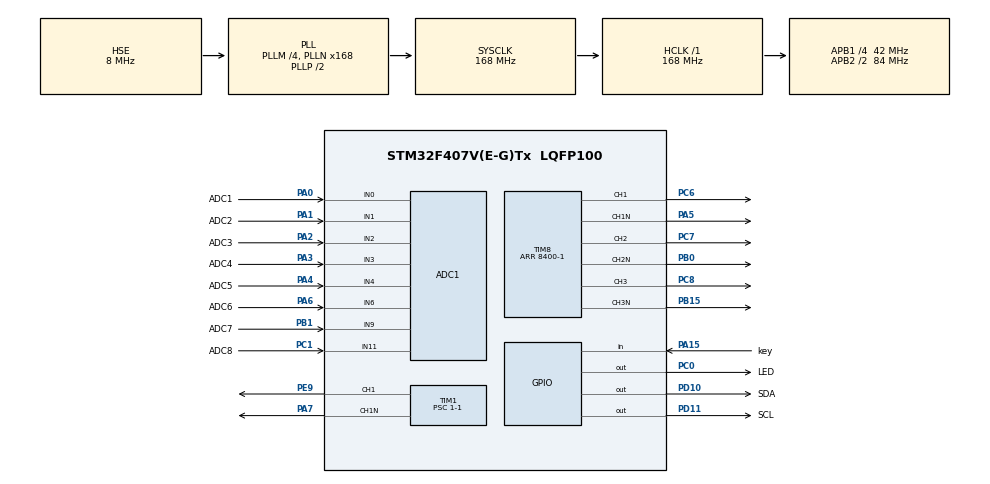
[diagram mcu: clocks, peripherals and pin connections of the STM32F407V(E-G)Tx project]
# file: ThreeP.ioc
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ADC1.Channel-14\#ChannelRegularConversion=ADC_CHANNEL_4
ADC1.Channel-15\#ChannelRegularConversion=ADC_CHANNEL_6
ADC1.Channel-16\#ChannelRegularConversion=ADC_CHANNEL_9
ADC1.Channel-17\#ChannelRegularConversion=ADC_CHANNEL_11
ADC1.Channel-5\#ChannelRegularConversion=ADC_CHANNEL_0
ADC1.Channel-6\#ChannelRegularConversion=ADC_CHANNEL_1
ADC1.Channel-7\#ChannelRegularConversion=ADC_CHANNEL_2
ADC1.Channel-9\#ChannelRegularConversion=ADC_CHANNEL_3
ADC1.ContinuousConvMode=ENABLE
ADC1.DMAContinuousRequests=ENABLE
ADC1.InjNumberOfConversion=0
ADC1.NbrOfConversion=8
ADC1.NbrOfConversionFlag=1
ADC1.Rank-14\#ChannelRegularConversion=5
ADC1.Rank-15\#ChannelRegularConversion=6
ADC1.Rank-16\#ChannelRegularConversion=7
ADC1.Rank-17\#ChannelRegularConversion=8
ADC1.Rank-5\#ChannelRegularConversion=1
ADC1.Rank-6\#ChannelRegularConversion=2
ADC1.Rank-7\#ChannelRegularConversion=3
ADC1.Rank-9\#ChannelRegularConversion=4
ADC1.SamplingTime-14\#ChannelRegularConversion=ADC_SAMPLETIME_15CYCLES
ADC1.SamplingTime-15\#ChannelRegularConversion=ADC_SAMPLETIME_15CYCLES
ADC1.SamplingTime-16\#ChannelRegularConversion=ADC_SAMPLETIME_15CYCLES
ADC1.SamplingTime-17\#ChannelRegularConversion=ADC_SAMPLETIME_15CYCLES
ADC1.SamplingTime-5\#ChannelRegularConversion=ADC_SAMPLETIME_15CYCLES
ADC1.SamplingTime-6\#ChannelRegularConversion=ADC_SAMPLETIME_15CYCLES
ADC1.SamplingTime-7\#ChannelRegularConversion=ADC_SAMPLETIME_15CYCLES
ADC1.SamplingTime-9\#ChannelRegularConversion=ADC_SAMPLETIME_15CYCLES
ADC1.ScanConvMode=ENABLE
ADC1.master=1
Dma.ADC1.0.Direction=DMA_PERIPH_TO_MEMORY
Dma.ADC1.0.FIFOMode=DMA_FIFOMODE_DISABLE
Dma.ADC1.0.Instance=DMA2_Stream0
Dma.ADC1.0.MemDataAlignment=DMA_MDATAALIGN_HALFWORD
Dma.ADC1.0.MemInc=DMA_MINC_ENABLE
Dma.ADC1.0.Mode=DMA_CIRCULAR
Dma.ADC1.0.PeriphDataAlignment=DMA_PDATAALIGN_HALFWORD
Dma.ADC1.0.PeriphInc=DMA_PINC_DISABLE
Dma.ADC1.0.Priority=DMA_PRIORITY_VERY_HIGH
Dma.Request0=ADC1
Mcu.Family=STM32F4
Mcu.Name=STM32F407V(E-G)Tx
Mcu.Package=LQFP100
NVIC.ADC_IRQn=true\:0\:0\:false\:false\:true\:true\:true
NVIC.DMA2_Stream0_IRQn=true\:0\:0\:false\:false\:true\:false\:true
NVIC.PriorityGroup=NVIC_PRIORITYGROUP_4
NVIC.TIM1_UP_TIM10_IRQn=true\:1\:0\:true\:false\:true\:true\:true
NVIC.TIM8_UP_TIM13_IRQn=true\:1\:0\:true\:false\:true\:true\:true
PA0-WKUP.GPIO_Label=ADC1
PA0-WKUP.Signal=ADCx_IN0
PA1.GPIO_Label=ADC2
PA1.Signal=ADCx_IN1
PA13.Mode=Serial_Wire
PA13.Signal=SYS_JTMS-SWDIO
PA14.Mode=Serial_Wire
PA14.Signal=SYS_JTCK-SWCLK
PA15.GPIO_Label=key
PA15.GPIO_PuPd=GPIO_PULLUP
PA15.Signal=GPIO_Input
PA2.GPIO_Label=ADC3
PA2.Signal=ADCx_IN2
PA3.GPIO_Label=ADC4
PA3.Signal=ADCx_IN3
PA4.GPIO_Label=ADC5
PA4.Signal=ADCx_IN4
PA5.Mode=PWM Generation1 CH1 CH1N
PA5.Signal=TIM8_CH1N
PA6.GPIO_Label=ADC6
PA6.Signal=ADCx_IN6
PA7.GPIO_PuPd=GPIO_NOPULL
PA7.GPIO_Speed=GPIO_SPEED_FREQ_HIGH
PA7.Mode=PWM Generation1 CH1 CH1N
PA7.Signal=TIM1_CH1N
PB0.Mode=PWM Generation2 CH2 CH2N
PB0.Signal=TIM8_CH2N
PB1.GPIO_Label=ADC7
PB1.Signal=ADCx_IN9
PB15.Mode=PWM Generation3 CH3 CH3N
PB15.Signal=TIM8_CH3N
PC0.GPIO_Label=LED
PC0.Signal=GPIO_Output
PC1.GPIO_Label=ADC8
PC1.Signal=ADCx_IN11
PC6.Signal=S_TIM8_CH1
PC7.Signal=S_TIM8_CH2
PC8.Signal=S_TIM8_CH3
PD10.GPIO_Label=SDA
PD10.Signal=GPIO_Output
PD11.GPIO_Label=SCL
PD11.Signal=GPIO_Output
PE9.GPIO_Speed=GPIO_SPEED_FREQ_HIGH
PE9.Signal=S_TIM1_CH1
PH0-OSC_IN.Mode=HSE-External-Oscillator
PH0-OSC_IN.Signal=RCC_OSC_IN
PH1-OSC_OUT.Mode=HSE-External-Oscillator
PH1-OSC_OUT.Signal=RCC_OSC_OUT
ProjectManager.HeapSize=0x2000
ProjectManager.StackSize=0x2000
ProjectManager.TargetToolchain=MDK-ARM V5.27
RCC.48MHZClocksFreq_Value=84000000
RCC.AHBFreq_Value=168000000
RCC.APB1CLKDivider=RCC_HCLK_DIV4
RCC.APB1Freq_Value=42000000
RCC.APB1TimFreq_Value=84000000
RCC.APB2CLKDivider=RCC_HCLK_DIV2
RCC.APB2Freq_Value=84000000
RCC.APB2TimFreq_Value=168000000
RCC.CortexFreq_Value=168000000
RCC.HCLKFreq_Value=168000000
RCC.HSE_VALUE=8000000
RCC.HSI_VALUE=16000000
RCC.LSE_VALUE=32768
RCC.PLLM=4
RCC.PLLN=168
RCC.PLLSourceVirtual=RCC_PLLSOURCE_HSE
RCC.SYSCLKFreq_VALUE=168000000
RCC.SYSCLKSource=RCC_SYSCLKSOURCE_PLLCLK
RCC.VCOOutputFreq_Value=336000000
SH.ADCx_IN0.0=ADC1_IN0,IN0
SH.ADCx_IN1.0=ADC1_IN1,IN1
SH.ADCx_IN11.0=ADC1_IN11,IN11
SH.ADCx_IN2.0=ADC1_IN2,IN2
SH.ADCx_IN3.0=ADC1_IN3,IN3
SH.ADCx_IN4.0=ADC1_IN4,IN4
SH.ADCx_IN6.0=ADC1_IN6,IN6
SH.ADCx_IN9.0=ADC1_IN9,IN9
SH.S_TIM1_CH1.0=TIM1_CH1,PWM Generation1 CH1 CH1N
SH.S_TIM8_CH1.0=TIM8_CH1,PWM Generation1 CH1 CH1N
SH.S_TIM8_CH2.0=TIM8_CH2,PWM Generation2 CH2 CH2N
SH.S_TIM8_CH3.0=TIM8_CH3,PWM Generation3 CH3 CH3N
TIM1.AutoReloadPreload=TIM_AUTORELOAD_PRELOAD_ENABLE
TIM1.Channel-PWM\ Generation1\ CH1\ CH1N=TIM_CHANNEL_1
TIM1.CounterMode=TIM_COUNTERMODE_CENTERALIGNED1
TIM1.DeadTime=100
TIM1.Period=8400-1
TIM1.Prescaler=1-1
TIM8.AutoReloadPreload=TIM_AUTORELOAD_PRELOAD_ENABLE
TIM8.Channel-PWM\ Generation1\ CH1\ CH1N=TIM_CHANNEL_1
TIM8.Channel-PWM\ Generation2\ CH2\ CH2N=TIM_CHANNEL_2
TIM8.Channel-PWM\ Generation3\ CH3\ CH3N=TIM_CHANNEL_3
TIM8.CounterMode=TIM_COUNTERMODE_CENTERALIGNED1
TIM8.DeadTime=100
TIM8.Period=8400-1
VP_TIM1_VS_ClockSourceINT.Mode=Internal
board=custom

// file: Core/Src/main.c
/* USER CODE BEGIN Header */
/**
  ******************************************************************************
  * @file           : main.c
  * @brief          : Main program body
  ******************************************************************************
  * @attention
  *
  * <h2><center>&copy; Copyright (c) 2021 STMicroelectronics.
  * All rights reserved.</center></h2>
  *
  * This software component is licensed by ST under BSD 3-Clause license,
  * the "License"; You may not use this file except in compliance with the
  * License. You may obtain a copy of the License at:
  *                        opensource.org/licenses/BSD-3-Clause
  *
  ******************************************************************************
  */
/* USER CODE END Header */
#include "main.h"
#include "adc.h"
#include "dma.h"
#include "tim.h"
#include "gpio.h"

/* USER CODE BEGIN Includes */
#include "control.h"

/* USER CODE END Includes */

/* USER CODE BEGIN PV */
float test_ang;
extern IPARK ipark,ipark_I;
extern int ang_flag;
/* USER CODE END PV */

void SystemClock_Config(void);

int main(void)
{

  /* MCU Configuration--------------------------------------------------------*/

  /* Reset of all peripherals, Initializes the Flash interface and the Systick. */
  HAL_Init();

  /* Configure the system clock */
  SystemClock_Config();

  /* Initialize all configured peripherals */
  MX_GPIO_Init();
  MX_DMA_Init();
  MX_TIM1_Init();
  MX_ADC1_Init();
  MX_TIM8_Init();
  /* USER CODE BEGIN 2 */
	Starttime();
	pid_param_init();
	OLED_Init();
	ipark.de=0.4;
	ipark_I.de=0.5;
	HAL_Delay(100);
  /* USER CODE END 2 */

  /* Infinite loop */
  /* USER CODE BEGIN WHILE */
	OLED_Clear();
	OLED_ShowString(0,0,"OUTV:",16);
	OLED_Refresh_Gram();

  while (1)
  {
//		HAL_Delay(100);
//		OLED_ShowNum(20,0,10,16,16);
    /* USER CODE END WHILE */

  }
}

void SystemClock_Config(void)
{
  RCC_OscInitTypeDef RCC_OscInitStruct = {0};
  RCC_ClkInitTypeDef RCC_ClkInitStruct = {0};

  /** Configure the main internal regulator output voltage
  */
  __HAL_RCC_PWR_CLK_ENABLE();
  __HAL_PWR_VOLTAGESCALING_CONFIG(PWR_REGULATOR_VOLTAGE_SCALE1);
  /** Initializes the RCC Oscillators according to the specified parameters
  * in the RCC_OscInitTypeDef structure.
  */
  RCC_OscInitStruct.OscillatorType = RCC_OSCILLATORTYPE_HSE;
  RCC_OscInitStruct.HSEState = RCC_HSE_ON;
  RCC_OscInitStruct.PLL.PLLState = RCC_PLL_ON;
  RCC_OscInitStruct.PLL.PLLSource = RCC_PLLSOURCE_HSE;
  RCC_OscInitStruct.PLL.PLLM = 4;
  RCC_OscInitStruct.PLL.PLLN = 168;
  RCC_OscInitStruct.PLL.PLLP = RCC_PLLP_DIV2;
  RCC_OscInitStruct.PLL.PLLQ = 4;
  if (HAL_RCC_OscConfig(&RCC_OscInitStruct) != HAL_OK)
  {
    Error_Handler();
  }
  /** Initializes the CPU, AHB and APB buses clocks
  */
  RCC_ClkInitStruct.ClockType = RCC_CLOCKTYPE_HCLK|RCC_CLOCKTYPE_SYSCLK
                              |RCC_CLOCKTYPE_PCLK1|RCC_CLOCKTYPE_PCLK2;
  RCC_ClkInitStruct.SYSCLKSource = RCC_SYSCLKSOURCE_PLLCLK;
  RCC_ClkInitStruct.AHBCLKDivider = RCC_SYSCLK_DIV1;
  RCC_ClkInitStruct.APB1CLKDivider = RCC_HCLK_DIV4;
  RCC_ClkInitStruct.APB2CLKDivider = RCC_HCLK_DIV2;

  if (HAL_RCC_ClockConfig(&RCC_ClkInitStruct, FLASH_LATENCY_5) != HAL_OK)
  {
    Error_Handler();
  }
}

void Error_Handler(void)
{
}

/************************ (C) COPYRIGHT STMicroelectronics *****END OF FILE****/
